# HDSC_HC32L157KX register map
Vendor: HDSC Co.Ltd; Series: ARMCM0P; File version: 1.2
CPU: CM0 r0p0, little endian, no MPU, no FPU, 3 interrupt priority bits
Registers are 8-bit, read-write, reset 0x0 unless marked. A register's access mark holds for its fields unless they carry their own. Offsets are from the block's base; [hi:lo] are bit positions.

## BUZZER
Base 0x4003C200
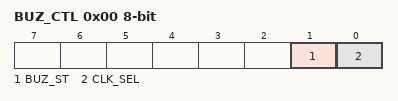
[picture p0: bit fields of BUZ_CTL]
0x00 BUZ_CTL
  [1] BUZ_ST, [0] CLK_SEL
0x04 BUZ_CNT

## CLOCK
Base 0x40010000
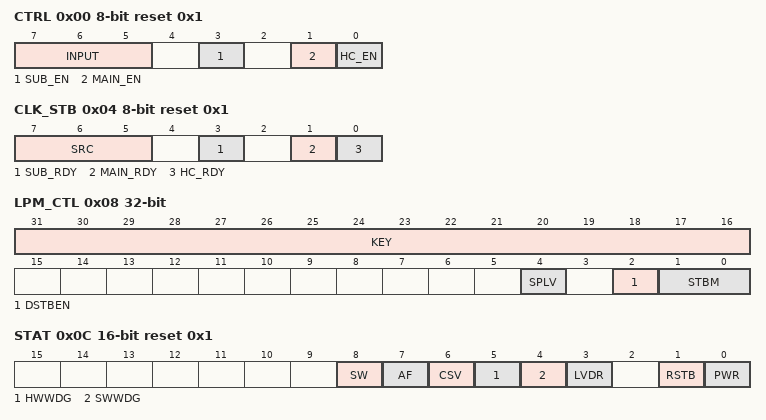
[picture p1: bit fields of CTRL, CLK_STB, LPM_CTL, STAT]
0x00 CTRL reset 0x1
  [7:5] INPUT, [3] SUB_EN, [1] MAIN_EN, [0] HC_EN
0x04 CLK_STB ro reset 0x1
  [7:5] SRC, [3] SUB_RDY, [1] MAIN_RDY, [0] HC_RDY
0x08 LPM_CTL 32-bit
  [31:16] KEY, [4] SPLV, [2] DSTBEN, [1:0] STBM
0x0C STAT 16-bit ro reset 0x1 (reset mask 0x1F3)
  [8] SW, [7] AF, [6] CSV, [5] HWWDG, [4] SWWDG, [3] LVDR, [1] RSTB, [0] PWR
0x10 BC_DIV
  [2:0] DIV
0x14 APB0_CTRL
  [1:0] DIV
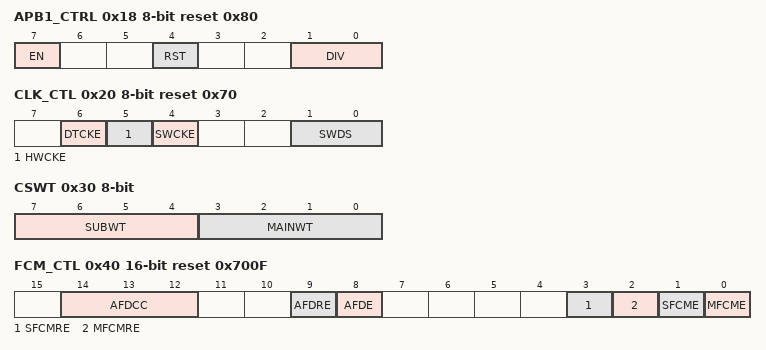
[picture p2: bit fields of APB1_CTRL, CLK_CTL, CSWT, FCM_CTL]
0x18 APB1_CTRL reset 0x80
  [7] EN, [4] RST, [1:0] DIV
0x20 CLK_CTL reset 0x70
  [6] DTCKE, [5] HWCKE, [4] SWCKE, [1:0] SWDS
0x30 CSWT
  [7:4] SUBWT, [3:0] MAINWT
0x40 FCM_CTL 16-bit reset 0x700F
  [14:12] AFDCC, [9] AFDRE, [8] AFDE, [3] SFCMRE, [2] MFCMRE, [1] SFCME, [0] MFCME
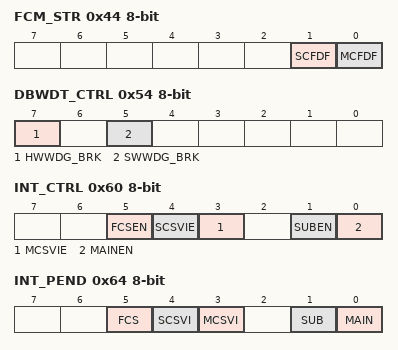
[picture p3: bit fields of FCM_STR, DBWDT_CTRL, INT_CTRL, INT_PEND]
0x44 FCM_STR ro
  [1] SCFDF, [0] MCFDF
0x48 AFDWH_CTL 16-bit reset 0xFFFF
  [15:0] AFDWH
0x4C AFDWL_CTL 16-bit
  [15:0] AFDWL
0x50 AFDC_CTL 16-bit ro
  [15:0] AFDC rw
0x54 DBWDT_CTRL
  [7] HWWDG_BRK, [5] SWWDG_BRK
0x60 INT_CTRL
  [5] FCSEN, [4] SCSVIE, [3] MCSVIE, [1] SUBEN, [0] MAINEN
0x64 INT_PEND ro
  [5] FCS, [4] SCSVI, [3] MCSVI, [1] SUB, [0] MAIN
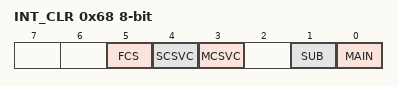
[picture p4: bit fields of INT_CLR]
0x68 INT_CLR wo
  [5] FCS, [4] SCSVC, [3] MCSVC, [1] SUB, [0] MAIN

## CTIOSEL03
Base 0x40025100
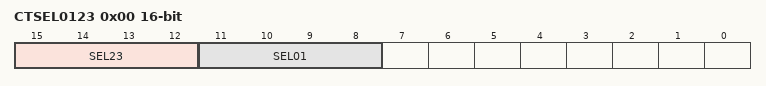
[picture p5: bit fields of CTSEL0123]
0x00 CTSEL0123 16-bit
  [15:12] SEL23, [11:8] SEL01

## CTIOSEL47
Base 0x40025300
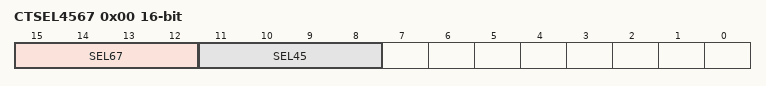
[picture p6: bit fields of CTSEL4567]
0x00 CTSEL4567 16-bit
  [15:12] SEL67, [11:8] SEL45

## CT0_PPG — desc CT_PPG
Base 0x40025000
Same registers: CT1_PPG 0x40025040, CT2_PPG 0x40025080, CT3_PPG 0x400250C0, CT4_PPG 0x40025200, CT5_PPG 0x40025240, CT6_PPG 0x40025280, CT7_PPG 0x400252C0
0x00 LWRR 16-bit
0x04 HWRR 16-bit
0x08 TCNT 16-bit ro
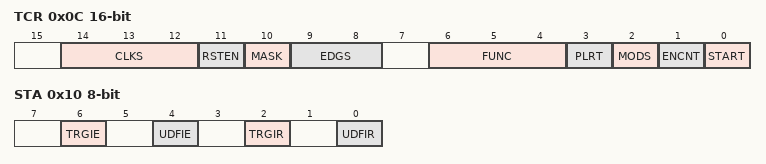
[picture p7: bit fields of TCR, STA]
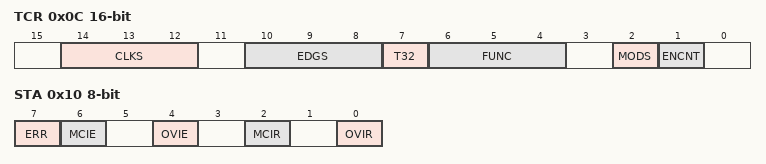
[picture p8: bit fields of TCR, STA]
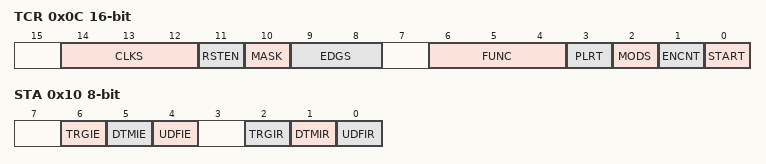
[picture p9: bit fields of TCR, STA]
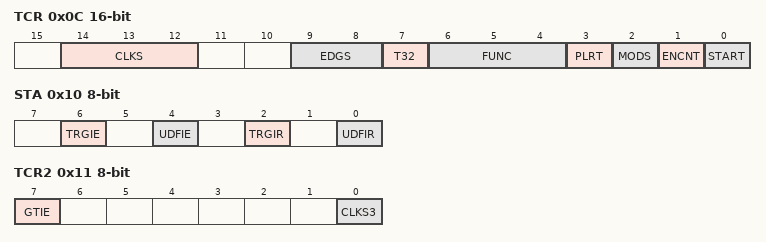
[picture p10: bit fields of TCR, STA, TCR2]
0x0C TCR 16-bit
  [14:12] CLKS, [11] RSTEN, [10] MASK, [9:8] EDGS, [6:4] FUNC, [3] PLRT, [2] MODS, [1] ENCNT, [0] START
0x10 STA
  [6] TRGIE, [4] UDFIE, [2] TRGIR, [0] UDFIR
0x11 TCR2
  [0] CLKS3

## CT0_PWC — desc CT_PWC
Base 0x40025000; alternate view of CT0_PPG
Same registers: CT1_PWC 0x40025040 (alternate view of CT1_PPG), CT2_PWC 0x40025080 (alternate view of CT2_PPG), CT3_PWC 0x400250C0 (alternate view of CT3_PPG), CT4_PWC 0x40025200 (alternate view of CT4_PPG), CT5_PWC 0x40025240 (alternate view of CT5_PPG), CT6_PWC 0x40025280 (alternate view of CT6_PPG), CT7_PWC 0x400252C0 (alternate view of CT7_PPG)
0x04 DBUF 16-bit ro
0x0C TCR 16-bit
  [14:12] CLKS, [10:8] EDGS, [7] T32, [6:4] FUNC, [2] MODS, [1] ENCNT
0x10 STA
  [7] ERR ro, [6] MCIE, [4] OVIE, [2] MCIR ro, [0] OVIR
0x11 TCR2
  [0] CLKS3

## CT0_PWM — desc CT_PWM
Base 0x40025000; alternate view of CT0_PPG
Same registers: CT1_PWM 0x40025040 (alternate view of CT1_PPG), CT2_PWM 0x40025080 (alternate view of CT2_PPG), CT3_PWM 0x400250C0 (alternate view of CT3_PPG), CT4_PWM 0x40025200 (alternate view of CT4_PPG), CT5_PWM 0x40025240 (alternate view of CT5_PPG), CT6_PWM 0x40025280 (alternate view of CT6_PPG), CT7_PWM 0x400252C0 (alternate view of CT7_PPG)
0x00 CSR 16-bit
0x04 DUT 16-bit
0x08 TCNT 16-bit ro
0x0C TCR 16-bit
  [14:12] CLKS, [11] RSTEN, [10] MASK, [9:8] EDGS, [6:4] FUNC, [3] PLRT, [2] MODS, [1] ENCNT, [0] START
0x10 STA
  [6] TRGIE, [5] DTMIE, [4] UDFIE, [2] TRGIR, [1] DTMIR, [0] UDFIR
0x11 TCR2
  [0] CLKS3

## CT0_RT — desc CT_RT
Base 0x40025000; alternate view of CT0_PPG
Same registers: CT1_RT 0x40025040 (alternate view of CT1_PPG), CT2_RT 0x40025080 (alternate view of CT2_PPG), CT3_RT 0x400250C0 (alternate view of CT3_PPG), CT4_RT 0x40025200 (alternate view of CT4_PPG), CT5_RT 0x40025240 (alternate view of CT5_PPG), CT6_RT 0x40025280 (alternate view of CT6_PPG), CT7_RT 0x400252C0 (alternate view of CT7_PPG)
0x00 CSR 16-bit
0x08 TCNT 16-bit ro
0x0C TCR 16-bit
  [14:12] CLKS, [9:8] EDGS, [7] T32, [6:4] FUNC, [3] PLRT, [2] MODS, [1] ENCNT, [0] START
0x10 STA
  [6] TRGIE, [4] UDFIE, [2] TRGIR, [0] UDFIR
0x11 TCR2
  [7] GTIE, [0] CLKS3
